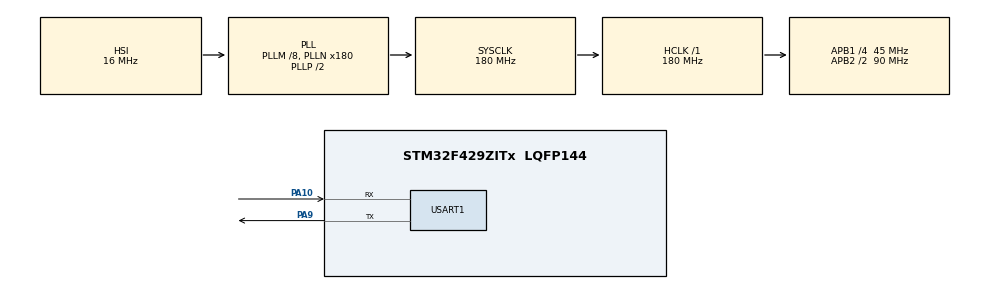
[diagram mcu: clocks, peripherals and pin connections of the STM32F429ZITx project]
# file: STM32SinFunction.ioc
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Mcu.Family=STM32F4
Mcu.Name=STM32F429ZITx
Mcu.Package=LQFP144
NVIC.PriorityGroup=NVIC_PRIORITYGROUP_4
PA10.Mode=Asynchronous
PA10.Signal=USART1_RX
PA9.Mode=Asynchronous
PA9.Signal=USART1_TX
ProjectManager.HeapSize=0x800
ProjectManager.StackSize=0x800
ProjectManager.TargetToolchain=STM32CubeIDE
RCC.48MHZClocksFreq_Value=90000000
RCC.AHBFreq_Value=180000000
RCC.APB1CLKDivider=RCC_HCLK_DIV4
RCC.APB1Freq_Value=45000000
RCC.APB1TimFreq_Value=90000000
RCC.APB2CLKDivider=RCC_HCLK_DIV2
RCC.APB2Freq_Value=90000000
RCC.APB2TimFreq_Value=180000000
RCC.CortexFreq_Value=180000000
RCC.HCLKFreq_Value=180000000
RCC.HSE_VALUE=25000000
RCC.HSI_VALUE=16000000
RCC.LSE_VALUE=32768
RCC.PLLM=8
RCC.PLLMUL=RCC_PLL_MUL9
RCC.PLLN=180
RCC.PRESCALERUSB=RCC_USBCLKSOURCE_PLL_DIV1_5
RCC.SYSCLKFreq_VALUE=180000000
RCC.SYSCLKSource=RCC_SYSCLKSOURCE_PLLCLK
RCC.SYSCLKSourceVirtual=RCC_SYSCLKSOURCE_PLLCLK
RCC.VCOOutputFreq_Value=360000000
STMicroelectronics.X-CUBE-AI.10.1.0.ActivationBufferSizeList=1900
STMicroelectronics.X-CUBE-AI.10.1.0.ActivationBuffers=pool0
STMicroelectronics.X-CUBE-AI.10.1.0.ActivationNames=pool0
STMicroelectronics.X-CUBE-AI.10.1.0.ActivationSizes=AI_SIN_MODEL_DATA_ACTIVATION_1_SIZE
STMicroelectronics.X-CUBE-AI.10.1.0.ApplicationCcDeviceJjApplication=ApplicationTemplate
STMicroelectronics.X-CUBE-AI.10.1.0.HeapSize=0x800
STMicroelectronics.X-CUBE-AI.10.1.0.InternalRamActivationBufferMaxSize=AI_SIN_MODEL_DATA_ACTIVATIONS_SIZE
STMicroelectronics.X-CUBE-AI.10.1.0.MaximumNumberOfInputLayer=1
STMicroelectronics.X-CUBE-AI.10.1.0.MaximumNumberOfOutputLayer=1
STMicroelectronics.X-CUBE-AI.10.1.0.MaximumSizeOfInputLayer=1
STMicroelectronics.X-CUBE-AI.10.1.0.MaximumSizeOfOutputLayer=1
STMicroelectronics.X-CUBE-AI.10.1.0.ModelActualCompression-5342aa192774c971bcde8751c2caa44079de0307042c7c20e83579a7eada1725=0.0
STMicroelectronics.X-CUBE-AI.10.1.0.ModelCompression-5342aa192774c971bcde8751c2caa44079de0307042c7c20e83579a7eada1725=Low
STMicroelectronics.X-CUBE-AI.10.1.0.ModelFlashOccupation-5342aa192774c971bcde8751c2caa44079de0307042c7c20e83579a7eada1725=10502
STMicroelectronics.X-CUBE-AI.10.1.0.ModelHashList=5342aa192774c971bcde8751c2caa44079de0307042c7c20e83579a7eada1725
STMicroelectronics.X-CUBE-AI.10.1.0.ModelKind-5342aa192774c971bcde8751c2caa44079de0307042c7c20e83579a7eada1725=TFLITE
STMicroelectronics.X-CUBE-AI.10.1.0.ModelMacc-5342aa192774c971bcde8751c2caa44079de0307042c7c20e83579a7eada1725=257
STMicroelectronics.X-CUBE-AI.10.1.0.ModelName-5342aa192774c971bcde8751c2caa44079de0307042c7c20e83579a7eada1725=sin_model
STMicroelectronics.X-CUBE-AI.10.1.0.ModelNameList=sin_model
STMicroelectronics.X-CUBE-AI.10.1.0.ModelRamOccupation-5342aa192774c971bcde8751c2caa44079de0307042c7c20e83579a7eada1725=1900
STMicroelectronics.X-CUBE-AI.10.1.0.ModelStructureFile-5342aa192774c971bcde8751c2caa44079de0307042c7c20e83579a7eada1725=D\:\\Code\\AI\\EdgeAI\\SinFunction\\sin_model.tflite
STMicroelectronics.X-CUBE-AI.10.1.0.ModelType-5342aa192774c971bcde8751c2caa44079de0307042c7c20e83579a7eada1725=STM32Cube.AI MCU runtime
STMicroelectronics.X-CUBE-AI.10.1.0.ReadyForCodeGeneration=true
STMicroelectronics.X-CUBE-AI.10.1.0.StackSize=0x800
STMicroelectronics.X-CUBE-AI.10.1.0.WorkingBufferStartAddrList=0xFFFFFFFF
STMicroelectronics.X-CUBE-AI.10.1.0.XAaCUBEAaAICcArtificialOoIntelligenceJjCore=true
STMicroelectronics.X-CUBE-AI.10.1.0.copyWeightToRam-5342aa192774c971bcde8751c2caa44079de0307042c7c20e83579a7eada1725=false
STMicroelectronics.X-CUBE-AI.10.1.0.customLayerConfigEnabled-5342aa192774c971bcde8751c2caa44079de0307042c7c20e83579a7eada1725=false
STMicroelectronics.X-CUBE-AI.10.1.0.noOnnxIoTranspose-5342aa192774c971bcde8751c2caa44079de0307042c7c20e83579a7eada1725=false
STMicroelectronics.X-CUBE-AI.10.1.0.useInputAllocation-5342aa192774c971bcde8751c2caa44079de0307042c7c20e83579a7eada1725=true
STMicroelectronics.X-CUBE-AI.10.1.0.useOutputAllocation-5342aa192774c971bcde8751c2caa44079de0307042c7c20e83579a7eada1725=true
USART1.VirtualMode=VM_ASYNC
VP_STMicroelectronics.X-CUBE-AI_VS_ArtificialOoIntelligenceJjXAaCUBEAaAI_10.1.0.Mode=ArtificialOoIntelligenceJjXAaCUBEAaAI
VP_STMicroelectronics.X-CUBE-AI_VS_DeviceJjApplication_10.1.0.Mode=DeviceJjApplication
board=custom

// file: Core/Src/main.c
/* USER CODE BEGIN Header */
/**
  ******************************************************************************
  * @file           : main.c
  * @brief          : Main program body
  ******************************************************************************
  * @attention
  *
  * Copyright (c) 2025 STMicroelectronics.
  * All rights reserved.
  *
  * This software is licensed under terms that can be found in the LICENSE file
  * in the root directory of this software component.
  * If no LICENSE file comes with this software, it is provided AS-IS.
  *
  ******************************************************************************
  */
/* USER CODE END Header */
#include "main.h"
#include "app_x-cube-ai.h"

UART_HandleTypeDef huart1;

void SystemClock_Config(void);
static void MX_GPIO_Init(void);
void MX_USART1_UART_Init(void);

int main(void)
{

  /* MCU Configuration--------------------------------------------------------*/

  /* Reset of all peripherals, Initializes the Flash interface and the Systick. */
  HAL_Init();

  /* Configure the system clock */
  SystemClock_Config();

  /* Initialize all configured peripherals */
  MX_GPIO_Init();
  MX_X_CUBE_AI_Init();
  /* USER CODE BEGIN 2 */
  MX_USART1_UART_Init();
  /* USER CODE END 2 */

  /* Infinite loop */
  while (1)
  {

  MX_X_CUBE_AI_Process();
  HAL_Delay(100000);
  }
}

void SystemClock_Config(void)
{
  RCC_OscInitTypeDef RCC_OscInitStruct = {0};
  RCC_ClkInitTypeDef RCC_ClkInitStruct = {0};

  /** Configure the main internal regulator output voltage
  */
  __HAL_RCC_PWR_CLK_ENABLE();
  __HAL_PWR_VOLTAGESCALING_CONFIG(PWR_REGULATOR_VOLTAGE_SCALE1);

  /** Initializes the RCC Oscillators according to the specified parameters
  * in the RCC_OscInitTypeDef structure.
  */
  RCC_OscInitStruct.OscillatorType = RCC_OSCILLATORTYPE_HSI;
  RCC_OscInitStruct.HSIState = RCC_HSI_ON;
  RCC_OscInitStruct.HSICalibrationValue = RCC_HSICALIBRATION_DEFAULT;
  RCC_OscInitStruct.PLL.PLLState = RCC_PLL_ON;
  RCC_OscInitStruct.PLL.PLLSource = RCC_PLLSOURCE_HSI;
  RCC_OscInitStruct.PLL.PLLM = 8;
  RCC_OscInitStruct.PLL.PLLN = 180;
  RCC_OscInitStruct.PLL.PLLP = RCC_PLLP_DIV2;
  RCC_OscInitStruct.PLL.PLLQ = 4;
  if (HAL_RCC_OscConfig(&RCC_OscInitStruct) != HAL_OK)
  {
    Error_Handler();
  }

  /** Activate the Over-Drive mode
  */
  if (HAL_PWREx_EnableOverDrive() != HAL_OK)
  {
    Error_Handler();
  }

  /** Initializes the CPU, AHB and APB buses clocks
  */
  RCC_ClkInitStruct.ClockType = RCC_CLOCKTYPE_HCLK|RCC_CLOCKTYPE_SYSCLK
                              |RCC_CLOCKTYPE_PCLK1|RCC_CLOCKTYPE_PCLK2;
  RCC_ClkInitStruct.SYSCLKSource = RCC_SYSCLKSOURCE_PLLCLK;
  RCC_ClkInitStruct.AHBCLKDivider = RCC_SYSCLK_DIV1;
  RCC_ClkInitStruct.APB1CLKDivider = RCC_HCLK_DIV4;
  RCC_ClkInitStruct.APB2CLKDivider = RCC_HCLK_DIV2;

  if (HAL_RCC_ClockConfig(&RCC_ClkInitStruct, FLASH_LATENCY_5) != HAL_OK)
  {
    Error_Handler();
  }
}

void MX_USART1_UART_Init(void)
{

  huart1.Instance = USART1;
  huart1.Init.BaudRate = 115200;
  huart1.Init.WordLength = UART_WORDLENGTH_8B;
  huart1.Init.StopBits = UART_STOPBITS_1;
  huart1.Init.Parity = UART_PARITY_NONE;
  huart1.Init.Mode = UART_MODE_TX_RX;
  huart1.Init.HwFlowCtl = UART_HWCONTROL_NONE;
  huart1.Init.OverSampling = UART_OVERSAMPLING_16;
  if (HAL_UART_Init(&huart1) != HAL_OK)
  {
    Error_Handler();
  }

}

static void MX_GPIO_Init(void)
{

  /* GPIO Ports Clock Enable */
  __HAL_RCC_GPIOA_CLK_ENABLE();

}

void Error_Handler(void)
{
  __disable_irq();
  while (1)
  {
  }
}
